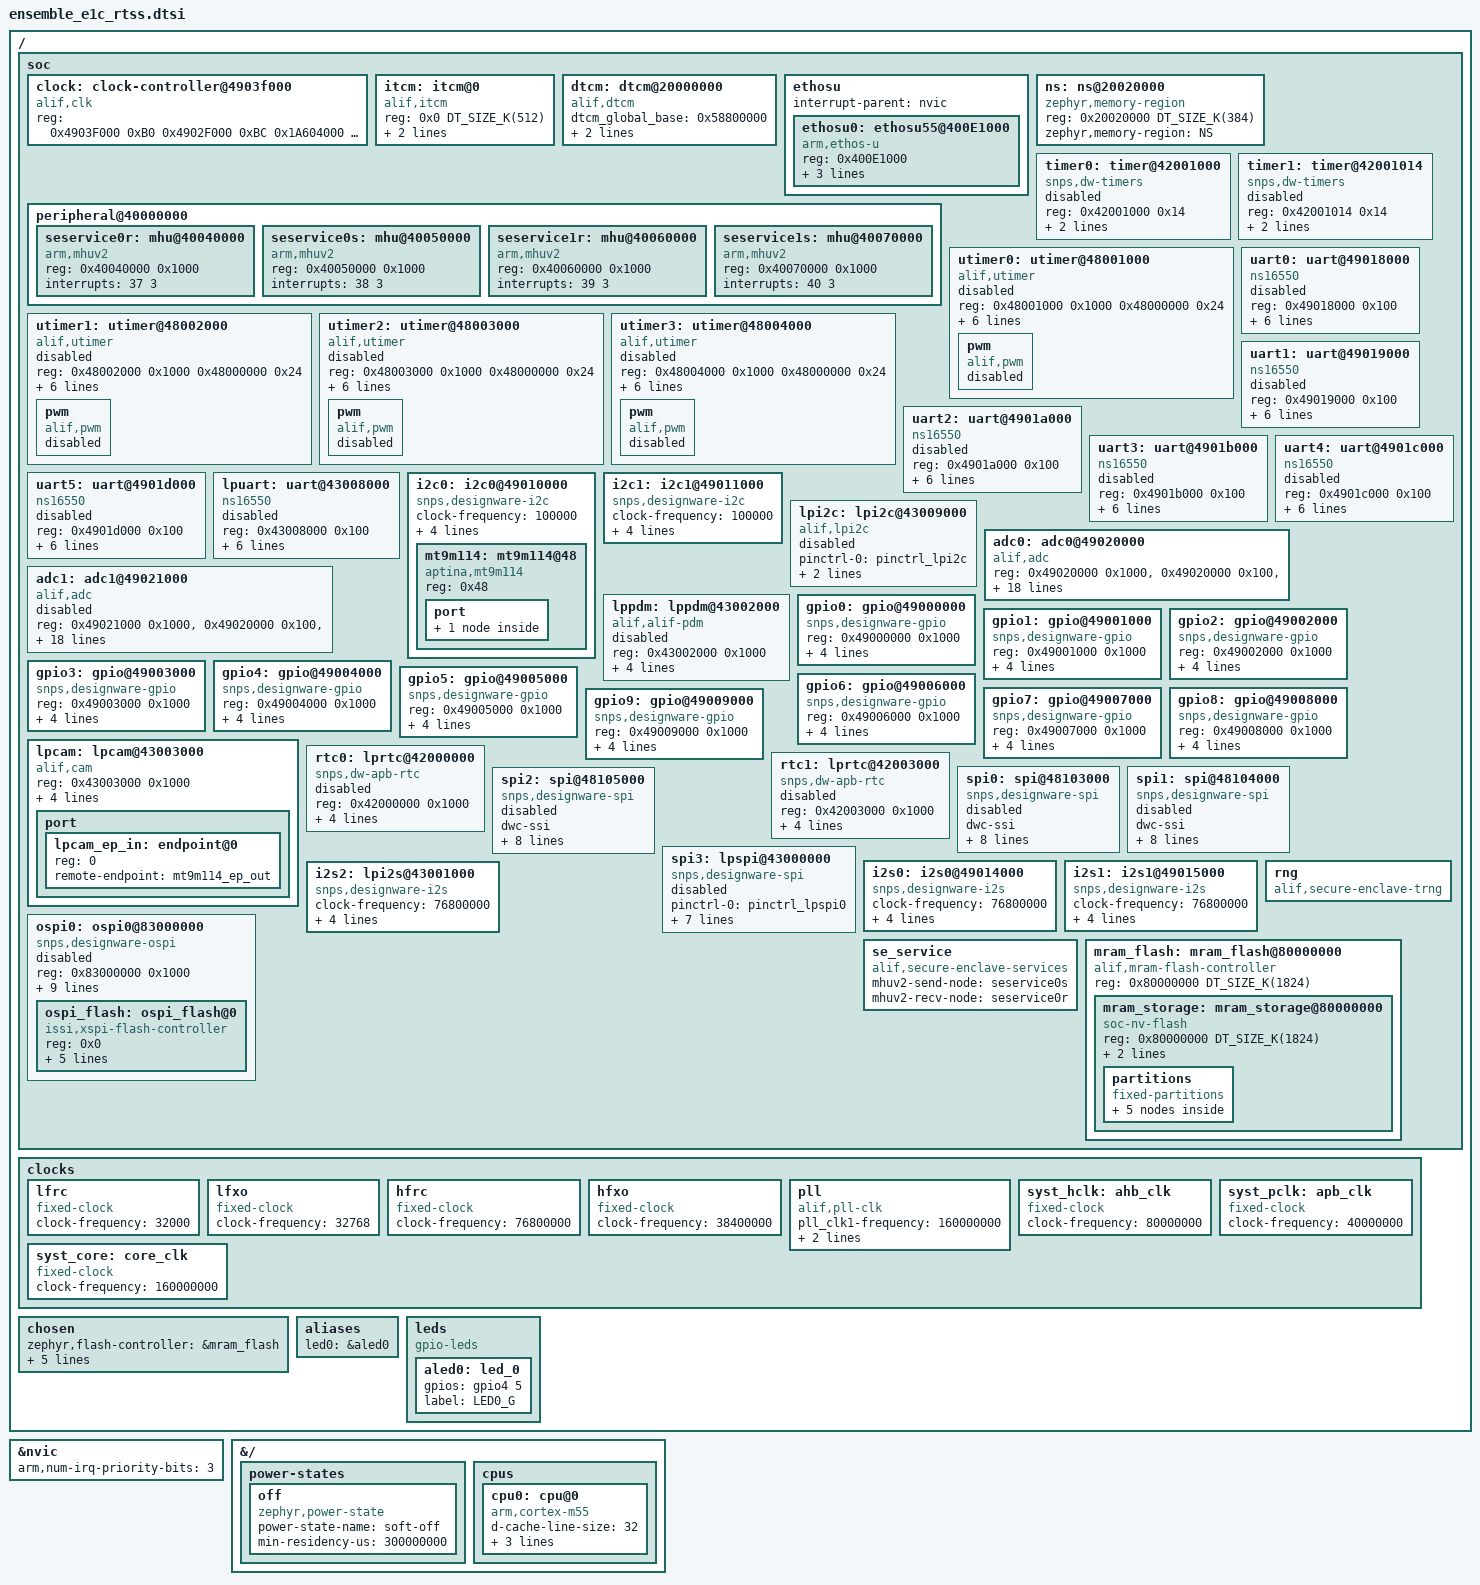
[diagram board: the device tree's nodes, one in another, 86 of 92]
/* Copyright (c) 2024 Alif Semiconductor
 *
 * SPDX-License-Identifier: Apache-2.0
 */
#include <arm/armv8.1-m.dtsi>
#include <zephyr/dt-bindings/timer/alif_utimer.h>
#include <zephyr/dt-bindings/pwm/pwm.h>
#include <zephyr/dt-bindings/clock/alif_balletto_clocks.h>
#include <mem.h>
/ {
	soc {
		clock: clock-controller@4903f000 {
			compatible = "alif,clk";
			reg =  <0x4903F000 0xB0
				0x4902F000 0xBC
				0x1A604000 0x44
				0x1A609000 0x14
				0x43007000 0x2C>;
			reg-names = "master_clkctrl",
				     "slave_clkctrl",
				     "aon_clkctrl",
				     "vbat_clkctrl",
				     "m55he_clkctrl";
			#clock-cells = <1>;
			status = "okay";
		};
		itcm: itcm@0 {
			compatible = "alif,itcm", "zephyr,memory-region";
			reg = <0x0 DT_SIZE_K(512)>;
			itcm_global_base = <0x58000000>;
			zephyr,memory-region = "ITCM";
		};

		dtcm: dtcm@20000000 {
			compatible = "alif,dtcm", "zephyr,memory-region";
			dtcm_global_base = <0x58800000>;
			reg = <0x20000000 DT_SIZE_K(1536)>;
			zephyr,memory-region = "DTCM";
		};

		ethosu {
			#address-cells = <1>;
			#size-cells = <0>;
			interrupt-parent = <&nvic>;
			ethosu0: ethosu55@400E1000 {
				compatible = "arm,ethos-u";
				reg = <0x400E1000>;
				interrupts = <55 3>;
				secure-enable;
				privilege-enable;
				status = "okay";
			};
		};

		ns: ns@20020000 {
			compatible = "zephyr,memory-region", "mmio-region";
			reg = <0x20020000 DT_SIZE_K(384)>;
			zephyr,memory-region = "NS";
		};

		peripheral@40000000 {
			#address-cells = < 0x1 >;
			#size-cells = < 0x1 >;
			ranges = < 0x0 0x40000000 0x2000000 >;

			seservice0r: mhu@40040000 {
				compatible = "arm,mhuv2";
				reg = < 0x40040000 0x1000 >;
				interrupts = < 37 3 >;
				interrupt-names = "rx";
			};
			seservice0s: mhu@40050000 {
				compatible = "arm,mhuv2";
				reg = < 0x40050000 0x1000 >;
				interrupts = < 38 3 >;
				interrupt-names = "tx";
			};
			seservice1r: mhu@40060000 {
				compatible = "arm,mhuv2";
				reg = < 0x40060000 0x1000 >;
				interrupts = < 39 3 >;
				interrupt-names = "rx";
			};
			seservice1s: mhu@40070000 {
				compatible = "arm,mhuv2";
				reg = < 0x40070000 0x1000 >;
				interrupts = < 40 3 >;
				interrupt-names = "tx";
			};
		};

		timer0: timer@42001000 {
			compatible = "snps,dw-timers";
			reg = <0x42001000 0x14>;
			interrupts = < 60 3 >;
			clocks = <&clock ALIF_LPTIMER0_S32K_CLK>;
			status = "disabled";
		};

		timer1: timer@42001014 {
			compatible = "snps,dw-timers";
			reg = <0x42001014 0x14>;
			interrupts = < 61 3 >;
			clocks = <&clock ALIF_LPTIMER1_S32K_CLK>;
			status = "disabled";
		};

		utimer0: utimer@48001000 {
			compatible = "alif,utimer";
			reg = <0x48001000 0x1000 0x48000000 0x24>;
			reg-names = "timer", "global";
			timer-id = <0>;
			clock-frequency = <160000000>;
			counter-direction = < ALIF_UTIMER_COUNTER_DIRECTION_UP >;
			driver-enable = < ALIF_UTIMER_DRIVER_A_OUTPUT_ENABLE >;
			status = "disabled";

			pwm {
				compatible = "alif,pwm";
				#pwm-cells = <3>;
				status = "disabled";
			};
		};

		utimer1: utimer@48002000 {
			compatible = "alif,utimer";
			reg = <0x48002000 0x1000 0x48000000 0x24>;
			reg-names = "timer", "global";
			timer-id = <1>;
			clock-frequency = <160000000>;
			counter-direction = < ALIF_UTIMER_COUNTER_DIRECTION_UP >;
			driver-enable = < ALIF_UTIMER_DRIVER_A_OUTPUT_ENABLE >;
			status = "disabled";

			pwm {
				compatible = "alif,pwm";
				#pwm-cells = <3>;
				status = "disabled";
			};
		};

		utimer2: utimer@48003000 {
			compatible = "alif,utimer";
			reg = <0x48003000 0x1000 0x48000000 0x24>;
			reg-names = "timer", "global";
			timer-id = <2>;
			clock-frequency = <160000000>;
			counter-direction = < ALIF_UTIMER_COUNTER_DIRECTION_UP >;
			driver-enable = < ALIF_UTIMER_DRIVER_A_OUTPUT_ENABLE >;
			status = "disabled";

			pwm {
				compatible = "alif,pwm";
				#pwm-cells = <3>;
				status = "disabled";
			};
		};

		utimer3: utimer@48004000 {
			compatible = "alif,utimer";
			reg = <0x48004000 0x1000 0x48000000 0x24>;
			reg-names = "timer", "global";
			timer-id = <3>;
			clock-frequency = <160000000>;
			counter-direction = < ALIF_UTIMER_COUNTER_DIRECTION_UP >;
			driver-enable = < ALIF_UTIMER_DRIVER_A_OUTPUT_ENABLE >;
			status = "disabled";

			pwm {
				compatible = "alif,pwm";
				#pwm-cells = <3>;
				status = "disabled";
			};
		};

		uart0: uart@49018000 {
			compatible = "ns16550";
			reg = <0x49018000 0x100>;
			/* SYST_PCLK (APB bus) 40MHz baud clock */
			clock-frequency = <40000000>;
			interrupts = <124 3>;
			reg-shift = <2>;
			current-speed = <115200>;
			pinctrl-0 = < &pinctrl_uart0 >;
			pinctrl-names = "default";
			fifo-size = <32>;
			status = "disabled";
		};

		uart1: uart@49019000 {
			compatible = "ns16550";
			reg = <0x49019000 0x100>;
			/* SYST_PCLK (APB bus) 40MHz baud clock */
			clock-frequency = <40000000>;
			interrupts = <125 3>;
			reg-shift = <2>;
			current-speed = <115200>;
			pinctrl-0 = < &pinctrl_uart1 >;
			pinctrl-names = "default";
			fifo-size = <32>;
			status = "disabled";
		};

		uart2: uart@4901a000 {
			compatible = "ns16550";
			reg = <0x4901a000 0x100>;
			/* SYST_PCLK (APB bus) 40MHz baud clock */
			clock-frequency = <40000000>;
			interrupts = <126 3>;
			reg-shift = <2>;
			current-speed = <115200>;
			pinctrl-0 = < &pinctrl_uart2 >;
			pinctrl-names = "default";
			fifo-size = <32>;
			status = "disabled";
		};

		uart3: uart@4901b000 {
			compatible = "ns16550";
			reg = <0x4901b000 0x100>;
			/* SYST_PCLK (APB bus) 40MHz baud clock */
			clock-frequency = <40000000>;
			interrupts = <127 3>;
			reg-shift = <2>;
			current-speed = <115200>;
			pinctrl-0 = < &pinctrl_uart3 >;
			pinctrl-names = "default";
			fifo-size = <32>;
			status = "disabled";
		};

		uart4: uart@4901c000 {
			compatible = "ns16550";
			reg = <0x4901c000 0x100>;
			/* SYST_PCLK (APB bus) 40MHz baud clock */
			clock-frequency = <40000000>;
			interrupts = <128 3>;
			reg-shift = <2>;
			current-speed = <115200>;
			pinctrl-0 = < &pinctrl_uart4 >;
			pinctrl-names = "default";
			fifo-size = <32>;
			status = "disabled";
		};

		uart5: uart@4901d000 {
			compatible = "ns16550";
			reg = <0x4901d000 0x100>;
			/* SYST_PCLK (APB bus) 40MHz baud clock */
			clock-frequency = <40000000>;
			interrupts = <129 3>;
			reg-shift = <2>;
			current-speed = <115200>;
			pinctrl-0 = < &pinctrl_uart5 >;
			pinctrl-names = "default";
			fifo-size = <32>;
			status = "disabled";
		};

		lpuart: uart@43008000 {
			compatible = "ns16550";
			reg = <0x43008000 0x100>;
			/* RTSS_HE_CLK 160MHz baud clock */
			clock-frequency = <160000000>;
			interrupts = <45 3>;
			reg-shift = <2>;
			current-speed = <115200>;
			pinctrl-0 = < &pinctrl_lpuart >;
			pinctrl-names = "default";
			fifo-size = <32>;
			status = "disabled";
		};

		i2c0: i2c0@49010000 {
			compatible = "snps,designware-i2c";
			clock-frequency = <100000>;
			#address-cells = <1>;
			#size-cells = <0>;
			reg = <0x49010000 0x1000>;
			pinctrl-0 = < &pinctrl_i2c0 >;
			pinctrl-names = "default";
			interrupt-parent = <&nvic>;
			interrupts = <132 3>;
			status = "okay";
			mt9m114: mt9m114@48{
				compatible = "aptina,mt9m114";
				reg = <0x48>;
				status = "okay";

				port {
					mt9m114_ep_out: endpoint {
						remote-endpoint = < &lpcam_ep_in >;
					};
				};
			};
		};

		i2c1: i2c1@49011000 {
			compatible = "snps,designware-i2c";
			clock-frequency = <100000>;
			#address-cells = <1>;
			#size-cells = <0>;
			reg = <0x49011000 0x1000>;
			pinctrl-0 = < &pinctrl_i2c1 >;
			pinctrl-names = "default";
			interrupt-parent = <&nvic>;
			interrupts = <133 3>;
			status = "okay";
		};

		lpi2c: lpi2c@43009000 {
			compatible = "alif,lpi2c";
			#address-cells = <1>;
			#size-cells = <0>;
			pinctrl-names = "default";
			pinctrl-0 = <&pinctrl_lpi2c>;
			reg = <0x43009000 0x100>;
			interrupts = <47 3>;
			status = "disabled";
		};

		adc0: adc0@49020000{
			compatible = "alif,adc";
			reg =	<0x49020000 0x1000>,
				<0x49020000 0x100>,
				<0x49023000 0x100>,
				<0x1A604000 0x100>;
			reg-names = "adc_reg", "analog_reg", "comp_reg", "aon_regs";

			comparator_threshold_a = <0x01>;
			comparator_threshold_b = <0x01>;
			comparator_threshold_comparasion = "ABOVE_THRESHOLD_A_AND_B";

			sample-width		= <16>;
			clock_div		= <2>;
			avg_sample_num		= <256>;
			shift_n_bits		= <8>;
			shift_direction		= "RIGHT_SHIFT";
			comparator_en;
			comparator_bias		= "2.5_MS/s";
			driver_instance		= "ADC_INSTANCE_ADC12_0";
			adc_channel_scan	= "SINGLE_CHANNEL_SCAN";
			adc_conversion_mode	= "SINGLE_SHOT_CONVERSION";
			/* pga_enable; */     /* This property is valid in differential mode only */
			pga_gain		= "ADC_PGA_GAIN_0_DB";
			pinctrl-0		= < &pinctrl_adc0 >;
			pinctrl-names		= "default";
			interrupts		= <151 3>,
						  <154 3>,
						  <157 3>,
						  <160 3>;
			interrupt-names = "continuous_intr",
					  "single_shot_intr",
					  "comparator_a_intr",
					  "comparator_b_intr";
			status = "okay";
		};

		adc1: adc1@49021000{
			compatible = "alif,adc";
			reg =	<0x49021000 0x1000>,
				<0x49020000 0x100>,
				<0x49023000 0x100>,
				<0x1A604000 0x100>;
			reg-names = "adc_reg", "analog_reg", "comp_reg", "aon_regs";

			comparator_threshold_a = <0x01>;
			comparator_threshold_b = <0x01>;
			comparator_threshold_comparasion = "ABOVE_THRESHOLD_A_AND_B";

			sample-width		= <16>;
			clock_div		= <2>;
			avg_sample_num		= <256>;
			shift_n_bits		= <8>;
			shift_direction		= "RIGHT_SHIFT";
			comparator_en;
			comparator_bias		= "2.5_MS/s";
			driver_instance		= "ADC_INSTANCE_ADC12_1";
			adc_channel_scan	= "SINGLE_CHANNEL_SCAN";
			adc_conversion_mode	= "SINGLE_SHOT_CONVERSION";
			/* pga_enable; */     /* This property is valid in differential mode only */
			pga_gain		= "ADC_PGA_GAIN_0_DB";
			pinctrl-0		= < &pinctrl_adc1 >;
			pinctrl-names		= "default";
			interrupts		= <152 3>,
						  <155 3>,
						  <158 3>,
						  <161 3>;
			interrupt-names		= "continuous_intr",
						  "single_shot_intr",
						  "comparator_a_intr",
						  "comparator_b_intr";
			status = "disabled";
		};

		lppdm: lppdm@43002000 {
			compatible = "alif,alif-pdm";
			reg = <0x43002000 0x1000>;
			interrupts = <49 3>;
			pinctrl-0 = < &pinctrl_lppdm >;
			pinctrl-names = "default";
			fifo_watermark = <5>;
			bypass_iir_filter = <1>;
			status = "disabled";
		};

		gpio0: gpio@49000000 {
			compatible = "snps,designware-gpio";
			reg = <0x49000000 0x1000>;
			ngpios = <8>;
			interrupts =	<179 3>, <180 3>,
					<181 3>, <182 3>,
					<183 3>, <184 3>,
					<185 3>, <186 3>;
			gpio-controller;
			#gpio-cells = <2>;
		};
		gpio1: gpio@49001000 {
			compatible = "snps,designware-gpio";
			reg = <0x49001000 0x1000>;
			ngpios = <8>;
			interrupts =	<187 3>, <188 3>,
					<189 3>, <190 3>,
					<191 3>, <192 3>,
					<193 3>, <194 3>;
			gpio-controller;
			#gpio-cells = <2>;
		};
		gpio2: gpio@49002000 {
			compatible = "snps,designware-gpio";
			reg = <0x49002000 0x1000>;
			ngpios = <8>;
			interrupts =	<195 3>, <196 3>,
					<197 3>, <198 3>,
					<199 3>, <200 3>,
					<201 3>, <202 3>;
			gpio-controller;
			#gpio-cells = <2>;
		};
		gpio3: gpio@49003000 {
			compatible = "snps,designware-gpio";
			reg = <0x49003000 0x1000>;
			ngpios = <8>;
			interrupts =	<203 3>, <204 3>,
					<205 3>, <206 3>,
					<207 3>, <208 3>,
					<209 3>, <210 3>;
			gpio-controller;
			#gpio-cells = <2>;
		};
		gpio4: gpio@49004000 {
			compatible = "snps,designware-gpio";
			reg = <0x49004000 0x1000>;
			ngpios = <8>;
			interrupts =	<211 3>, <212 3>,
					<213 3>, <214 3>,
					<215 3>, <216 3>,
					<217 3>, <218 3>;
			gpio-controller;
			#gpio-cells = <2>;
		};
		gpio5: gpio@49005000 {
			compatible = "snps,designware-gpio";
			reg = <0x49005000 0x1000>;
			ngpios = <8>;
			interrupts =	<219 3>, <220 3>,
					<221 3>, <222 3>,
					<223 3>, <224 3>,
					<225 3>, <226 3>;
			gpio-controller;
			#gpio-cells = <2>;
		};
		gpio6: gpio@49006000 {
			compatible = "snps,designware-gpio";
			reg = <0x49006000 0x1000>;
			ngpios = <8>;
			interrupts =	<227 3>, <228 3>,
					<229 3>, <230 3>,
					<231 3>, <232 3>,
					<233 3>, <234 3>;
			gpio-controller;
			#gpio-cells = <2>;
		};
		gpio7: gpio@49007000 {
			compatible = "snps,designware-gpio";
			reg = <0x49007000 0x1000>;
			ngpios = <8>;
			interrupts =	<235 3>, <236 3>,
					<237 3>, <238 3>,
					<239 3>, <240 3>,
					<241 3>, <242 3>;
			gpio-controller;
			#gpio-cells = <2>;
		};

		gpio8: gpio@49008000 {
			compatible = "snps,designware-gpio";
			reg = <0x49008000 0x1000>;
			ngpios = <8>;
			interrupts =	<243 3>, <244 3>,
					<245 3>, <246 3>,
					<247 3>, <248 3>,
					<249 3>, <250 3>;
			gpio-controller;
			#gpio-cells = <2>;
		};
		gpio9: gpio@49009000 {
			compatible = "snps,designware-gpio";
			reg = <0x49009000 0x1000>;
			ngpios = <8>;
			interrupts =	<251 3>, <252 3>,
					<253 3>, <254 3>,
					<255 3>, <256 3>,
					<257 3>, <258 3>;
			gpio-controller;
			#gpio-cells = <2>;
		};

		lpcam: lpcam@43003000 {
			compatible = "alif,cam";
			reg = <0x43003000 0x1000>;
			interrupts = <54 3>;

			pinctrl-0 = < &pinctrl_lpcam >;
			pinctrl-names = "default";

			sensor = <&mt9m114>;
			lp-cam;
			status = "okay";
			port {
				#address-cells = <1>;
				#size-cells = <0>;

				lpcam_ep_in: endpoint@0 {
					reg = <0>;
					remote-endpoint = <&mt9m114_ep_out>;
				};
			};
		};

		rtc0: lprtc@42000000 {
			compatible = "snps,dw-apb-rtc";
			reg = <0x42000000 0x1000>;
			interrupts = <58 3>;
			clock-frequency = <32768>;
			prescaler = <0>;
			load-value = <0>;
			status = "disabled";
		};
		rtc1: lprtc@42003000 {
			compatible = "snps,dw-apb-rtc";
			reg = <0x42003000 0x1000>;
			interrupts = <59 3>;
			clock-frequency = <32768>;
			prescaler = <0>;
			load-value = <0>;
			status = "disabled";
		};

		spi0: spi@48103000 {
			dwc-ssi;
			compatible = "snps,designware-spi";
			#address-cells = <1>;
			#size-cells = <0>;
			pinctrl-0 = < &pinctrl_spi0 >;
			pinctrl-names = "default";
			reg = <0x48103000 0x1000>;
			interrupt-parent = <&nvic>;
			interrupts = <137 3>;
			cs-gpios = <&gpio5 3 0>;
			clocks = <&syst_hclk>;
			fifo-depth = <16>;
			max-xfer-size = <32>;
			status = "disabled";
		};
		spi1: spi@48104000 {
			dwc-ssi;
			compatible = "snps,designware-spi";
			#address-cells = <1>;
			#size-cells = <0>;
			pinctrl-0 = < &pinctrl_spi1 >;
			pinctrl-names = "default";
			reg = <0x48104000 0x1000>;
			interrupt-parent = <&nvic>;
			interrupts = <138 3>;
			cs-gpios = <&gpio8 7 0>;
			clocks = <&syst_hclk>;
			fifo-depth = <16>;
			max-xfer-size = <32>;
			status = "disabled";
		};
		spi2: spi@48105000 {
			dwc-ssi;
			compatible = "snps,designware-spi";
			#address-cells = <1>;
			#size-cells = <0>;
			pinctrl-0 = < &pinctrl_spi2 >;
			pinctrl-names = "default";
			reg = <0x48105000 0x1000>;
			interrupt-parent = <&nvic>;
			interrupts = <139 3>;
			cs-gpios = <&gpio4 5 0>;
			clocks = <&syst_hclk>;
			fifo-depth = <16>;
			max-xfer-size = <32>;
			status = "disabled";
		};
		spi3: lpspi@43000000 {
			compatible = "snps,designware-spi";
			#address-cells = <1>;
			#size-cells = <0>;
			pinctrl-0 = < &pinctrl_lpspi0 >;
			pinctrl-names = "default";
			reg = <0x43000000 0x1000>;
			interrupt-parent = <&nvic>;
			interrupts = <46 3>;
			cs-gpios = <&gpio2 0 0>;
			clocks = <&syst_core>;
			fifo-depth = <16>;
			max-xfer-size = <32>;
			status = "disabled";
		};
		i2s0: i2s0@49014000 {
			compatible = "snps,designware-i2s";
			clock-frequency = <76800000>;
			driver_instance	= "I2S_INSTANCE_0";
			reg = <0x49014000 0x1000>;
			pinctrl-names = "default";
			pinctrl-0 = <&pinctrl_i2s0>;
			interrupts = <141 3>;
		};
		i2s1: i2s1@49015000 {
			compatible = "snps,designware-i2s";
			clock-frequency = <76800000>;
			driver_instance	= "I2S_INSTANCE_1";
			reg = <0x49015000 0x1000>;
			pinctrl-names = "default";
			pinctrl-0 = <&pinctrl_i2s1>;
			interrupts = <142 3>;
		};
		i2s2: lpi2s@43001000 {
			compatible = "snps,designware-i2s";
			clock-frequency = <76800000>;
			driver_instance	= "I2S_INSTANCE_4";
			reg = <0x43001000 0x1000>;
			pinctrl-names = "default";
			pinctrl-0 = <&pinctrl_lpi2s>;
			interrupts = <48 3>;
		};
		ospi0: ospi0@83000000 {
			compatible = "snps,designware-ospi";
			#address-cells = <1>;
			#size-cells = <0>;
			reg = <0x83000000 0x1000>;
			pinctrl-0 = <&pinctrl_ospi0>;
			pinctrl-names = "default";
			interrupt-parent = <&nvic>;
			interrupts = <96 3>;
			aes-reg = <0x83001000 0x100>;
			bus-speed = <10000000>;
			cs-pin = <0>;
			ddr-drive-edge;
			rx-ds-delay = <11>;
			tx-fifo-threshold = <64>;
			status = "disabled";

			ospi_flash: ospi_flash@0 {
				compatible = "issi,xspi-flash-controller";
				reg = <0x0>;
				erase-value = <0xff>;
				num-of-sector = <8192>;
				page-size = <256>;
				sector-size = <4096>;
				write-block-size = <2>;
			};
		};
		rng: rng {
			compatible = "alif,secure-enclave-trng";
			status = "okay";
		};
		se_service: se_service {
			compatible = "alif,secure-enclave-services";
			mhuv2-send-node = <&seservice0s>;
			mhuv2-recv-node = <&seservice0r>;
			status = "okay";
		};
		mram_flash: mram_flash@80000000 {
			compatible = "alif,mram-flash-controller";
			/* Usable MRAM size for applications is 1824 KB */
			reg = <0x80000000 DT_SIZE_K(1824)>;

			#address-cells = <1>;
			#size-cells = <1>;
			mram_storage: mram_storage@80000000 {
				compatible = "soc-nv-flash";
				reg = <0x80000000 DT_SIZE_K(1824)>;
				erase-block-size = <1024>;
				write-block-size = <16>;
			};
		};
	};
	clocks {
		lfrc: lfrc {
			compatible = "fixed-clock";
			clock-frequency = <32000>;
			status = "okay";
			#clock-cells = <0>;
		};
		lfxo: lfxo {
			compatible = "fixed-clock";
			clock-frequency = <32768>;
			status = "okay";
			#clock-cells = <0>;
		};
		hfrc: hfrc {
			compatible = "fixed-clock";
			clock-frequency = <76800000>;
			status = "okay";
			#clock-cells = <0>;
		};
		hfxo: hfxo {
			compatible = "fixed-clock";
			clock-frequency = <38400000>;
			status = "okay";
			#clock-cells = <0>;
		};
		pll: pll {
			compatible = "alif,pll-clk";
			pll_clk1-frequency = <160000000>;
			pll_clk2-frequency = <120000000>;
			pll_clk3-frequency = <480000000>;
			status = "okay";
		};
		syst_hclk: ahb_clk {
			compatible = "fixed-clock";
			clock-frequency = <80000000>;
			#clock-cells = <0>;
		};
		syst_pclk: apb_clk {
			compatible = "fixed-clock";
			clock-frequency = <40000000>;
			#clock-cells = <0>;
		};
		syst_core: core_clk {
			compatible = "fixed-clock";
			clock-frequency = <160000000>;
			#clock-cells = <0>;
		};
	};
	chosen {
		zephyr,flash-controller = &mram_flash;
		zephyr,flash = &mram_storage;
		zephyr,code-partition = &slot0_partition;
		zephyr,sram = &dtcm;
		zephyr,dtcm = &dtcm;
		zephyr,entropy = &rng;
	};
	aliases {
		led0 = &aled0;
	};
	leds {
		compatible = "gpio-leds";
		aled0: led_0 {
			gpios = <&gpio4 5 0>;
			label = "LED0_G";
		};
	};
};

&mram_storage {
	partitions {
		compatible = "fixed-partitions";
		#address-cells = <1>;
		#size-cells = <1>;

		boot_partition: partition@0 {
			label = "mcuboot";
			reg = <0x00000000 DT_SIZE_K(64)>;
			read-only;
		};

		slot0_partition: partition@10000 {
			label = "image-0";
			reg = <0x00010000 DT_SIZE_K(843)>;
		};

		slot1_partition: partition@E2C00 {
			label = "image-1";
			reg = <0x000E2C00 DT_SIZE_K(843)>;
		};

		scratch_partition: partition@1B5800 {
			label = "image-scratch";
			reg = <0x001B5800 DT_SIZE_K(64)>;
		};

		storage_partition: partition@1C5800 {
			label = "storage";
			reg = <0x001C5800 DT_SIZE_K(10)>;
		};
	};
};

&nvic {
	arm,num-irq-priority-bits = <3>;
};

&{/} {
	power-states {
		off: off {
			compatible = "zephyr,power-state";
			power-state-name = "soft-off";
			min-residency-us = < 300000000 >;
		};
	};
	cpus {
		#address-cells = <1>;
		#size-cells = <0>;
		cpu0: cpu@0 {
			device_type = "cpu";
			compatible = "arm,cortex-m55";
			d-cache-line-size = <32>;
			i-cache-line-size = <32>;
			reg = <0>;
			cpu-power-states = <&off>;
		};
	};
};
